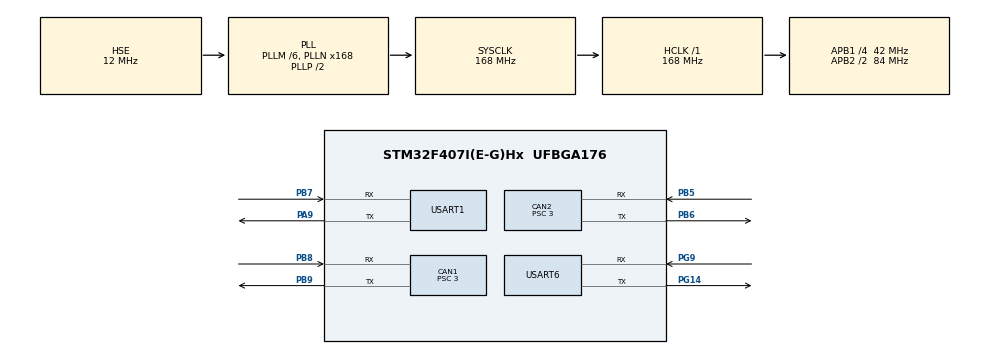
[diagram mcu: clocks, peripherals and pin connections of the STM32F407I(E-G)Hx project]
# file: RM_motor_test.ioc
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CAN1.BS1=CAN_BS1_10TQ
CAN1.BS2=CAN_BS2_3TQ
CAN1.CalculateBaudRate=1000000
CAN1.CalculateTimeBit=1000
CAN1.CalculateTimeQuantum=71.42857142857143
CAN1.Prescaler=3
CAN2.BS1=CAN_BS1_10TQ
CAN2.BS2=CAN_BS2_3TQ
CAN2.CalculateBaudRate=1000000
CAN2.CalculateTimeBit=1000
CAN2.CalculateTimeQuantum=71.42857142857143
CAN2.Prescaler=3
FREERTOS.Tasks01=motor_3508,-3,128,control_3508,Default,NULL,Dynamic,NULL,NULL;motor_6020,0,128,control_6020,Default,NULL,Dynamic,NULL,NULL
Mcu.Family=STM32F4
Mcu.Name=STM32F407I(E-G)Hx
Mcu.Package=UFBGA176
NVIC.CAN1_RX0_IRQn=true\:5\:0\:false\:false\:true\:true\:true\:true\:true
NVIC.CAN2_RX0_IRQn=true\:5\:0\:false\:false\:true\:true\:true\:true\:true
NVIC.PriorityGroup=NVIC_PRIORITYGROUP_4
NVIC.USART1_IRQn=true\:5\:0\:false\:false\:true\:true\:true\:true\:true
NVIC.USART6_IRQn=true\:5\:0\:false\:false\:true\:true\:true\:true\:true
PA13.Mode=Serial_Wire
PA13.Signal=SYS_JTMS-SWDIO
PA14.Mode=Serial_Wire
PA14.Signal=SYS_JTCK-SWCLK
PA9.Mode=Asynchronous
PA9.Signal=USART1_TX
PB5.Mode=CAN_Activate
PB5.Signal=CAN2_RX
PB6.Mode=CAN_Activate
PB6.Signal=CAN2_TX
PB7.Mode=Asynchronous
PB7.Signal=USART1_RX
PB8.Mode=CAN_Activate
PB8.Signal=CAN1_RX
PB9.Mode=CAN_Activate
PB9.Signal=CAN1_TX
PG14.Mode=Asynchronous
PG14.Signal=USART6_TX
PG9.Mode=Asynchronous
PG9.Signal=USART6_RX
PH0-OSC_IN.Mode=HSE-External-Oscillator
PH0-OSC_IN.Signal=RCC_OSC_IN
PH1-OSC_OUT.Mode=HSE-External-Oscillator
PH1-OSC_OUT.Signal=RCC_OSC_OUT
ProjectManager.HeapSize=0x200
ProjectManager.StackSize=0x400
ProjectManager.TargetToolchain=MDK-ARM V5
RCC.48MHZClocksFreq_Value=84000000
RCC.AHBFreq_Value=168000000
RCC.APB1CLKDivider=RCC_HCLK_DIV4
RCC.APB1Freq_Value=42000000
RCC.APB1TimFreq_Value=84000000
RCC.APB2CLKDivider=RCC_HCLK_DIV2
RCC.APB2Freq_Value=84000000
RCC.APB2TimFreq_Value=168000000
RCC.CortexFreq_Value=168000000
RCC.HCLKFreq_Value=168000000
RCC.HSE_VALUE=12000000
RCC.HSI_VALUE=16000000
RCC.LSE_VALUE=32768
RCC.PLLM=6
RCC.PLLN=168
RCC.PLLSourceVirtual=RCC_PLLSOURCE_HSE
RCC.SYSCLKFreq_VALUE=168000000
RCC.SYSCLKSource=RCC_SYSCLKSOURCE_PLLCLK
RCC.VCOOutputFreq_Value=336000000
USART1.VirtualMode=VM_ASYNC
USART6.VirtualMode=VM_ASYNC
VP_FREERTOS_VS_CMSIS_V1.Mode=CMSIS_V1
board=custom

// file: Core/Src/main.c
/* USER CODE BEGIN Header */
/**
  ******************************************************************************
  * @file           : main.c
  * @brief          : Main program body
  ******************************************************************************
  * @attention
  *
  * Copyright (c) 2025 STMicroelectronics.
  * All rights reserved.
  *
  * This software is licensed under terms that can be found in the LICENSE file
  * in the root directory of this software component.
  * If no LICENSE file comes with this software, it is provided AS-IS.
  *
  ******************************************************************************
  */
/* USER CODE END Header */
#include "main.h"
#include "cmsis_os.h"
#include "can.h"
#include "usart.h"
#include "gpio.h"

void SystemClock_Config(void);
void MX_FREERTOS_Init(void);

int main(void)
{

  /* MCU Configuration--------------------------------------------------------*/

  /* Reset of all peripherals, Initializes the Flash interface and the Systick. */
  HAL_Init();

  /* Configure the system clock */
  SystemClock_Config();

  /* Initialize all configured peripherals */
  MX_GPIO_Init();
  MX_CAN1_Init();
  MX_CAN2_Init();
  MX_USART1_UART_Init();
  MX_USART6_UART_Init();

  /* Call init function for freertos objects (in cmsis_os2.c) */
  MX_FREERTOS_Init();

  /* Start scheduler */
  osKernelStart();

  /* We should never get here as control is now taken by the scheduler */

  /* Infinite loop */
  while (1)
  {

  }
}

void SystemClock_Config(void)
{
  RCC_OscInitTypeDef RCC_OscInitStruct = {0};
  RCC_ClkInitTypeDef RCC_ClkInitStruct = {0};

  /** Configure the main internal regulator output voltage
  */
  __HAL_RCC_PWR_CLK_ENABLE();
  __HAL_PWR_VOLTAGESCALING_CONFIG(PWR_REGULATOR_VOLTAGE_SCALE1);

  /** Initializes the RCC Oscillators according to the specified parameters
  * in the RCC_OscInitTypeDef structure.
  */
  RCC_OscInitStruct.OscillatorType = RCC_OSCILLATORTYPE_HSE;
  RCC_OscInitStruct.HSEState = RCC_HSE_ON;
  RCC_OscInitStruct.PLL.PLLState = RCC_PLL_ON;
  RCC_OscInitStruct.PLL.PLLSource = RCC_PLLSOURCE_HSE;
  RCC_OscInitStruct.PLL.PLLM = 6;
  RCC_OscInitStruct.PLL.PLLN = 168;
  RCC_OscInitStruct.PLL.PLLP = RCC_PLLP_DIV2;
  RCC_OscInitStruct.PLL.PLLQ = 4;
  if (HAL_RCC_OscConfig(&RCC_OscInitStruct) != HAL_OK)
  {
    Error_Handler();
  }

  /** Initializes the CPU, AHB and APB buses clocks
  */
  RCC_ClkInitStruct.ClockType = RCC_CLOCKTYPE_HCLK|RCC_CLOCKTYPE_SYSCLK
                              |RCC_CLOCKTYPE_PCLK1|RCC_CLOCKTYPE_PCLK2;
  RCC_ClkInitStruct.SYSCLKSource = RCC_SYSCLKSOURCE_PLLCLK;
  RCC_ClkInitStruct.AHBCLKDivider = RCC_SYSCLK_DIV1;
  RCC_ClkInitStruct.APB1CLKDivider = RCC_HCLK_DIV4;
  RCC_ClkInitStruct.APB2CLKDivider = RCC_HCLK_DIV2;

  if (HAL_RCC_ClockConfig(&RCC_ClkInitStruct, FLASH_LATENCY_5) != HAL_OK)
  {
    Error_Handler();
  }
}

void Error_Handler(void)
{
  __disable_irq();
  while (1)
  {
  }
}

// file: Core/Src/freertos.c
/* USER CODE BEGIN Header */
/**
  ******************************************************************************
  * File Name          : freertos.c
  * Description        : Code for freertos applications
  ******************************************************************************
  * @attention
  *
  * Copyright (c) 2025 STMicroelectronics.
  * All rights reserved.
  *
  * This software is licensed under terms that can be found in the LICENSE file
  * in the root directory of this software component.
  * If no LICENSE file comes with this software, it is provided AS-IS.
  *
  ******************************************************************************
  */
/* USER CODE END Header */

#include "FreeRTOS.h"
#include "task.h"
#include "main.h"
#include "cmsis_os.h"
#include "CAN_receive.h"
#include "usart.h"

osThreadId motor_3508Handle;
osThreadId motor_6020Handle;

void control_3508(void const * argument);
void control_6020(void const * argument);

void MX_FREERTOS_Init(void); /* (MISRA C 2004 rule 8.1) */

/* GetIdleTaskMemory prototype (linked to static allocation support) */
void vApplicationGetIdleTaskMemory( StaticTask_t **ppxIdleTaskTCBBuffer, StackType_t **ppxIdleTaskStackBuffer, uint32_t *pulIdleTaskStackSize );

/* USER CODE BEGIN GET_IDLE_TASK_MEMORY */
static StaticTask_t xIdleTaskTCBBuffer;
static StackType_t xIdleStack[configMINIMAL_STACK_SIZE];

void vApplicationGetIdleTaskMemory( StaticTask_t **ppxIdleTaskTCBBuffer, StackType_t **ppxIdleTaskStackBuffer, uint32_t *pulIdleTaskStackSize )
{
  *ppxIdleTaskTCBBuffer = &xIdleTaskTCBBuffer;
  *ppxIdleTaskStackBuffer = &xIdleStack[0];
  *pulIdleTaskStackSize = configMINIMAL_STACK_SIZE;
  /* place for user code */
}
/* USER CODE END GET_IDLE_TASK_MEMORY */

void MX_FREERTOS_Init(void) {

  /* Create the thread(s) */
  /* definition and creation of motor_3508 */
  osThreadDef(motor_3508, control_3508, osPriorityIdle, 0, 128);
  motor_3508Handle = osThreadCreate(osThread(motor_3508), NULL);

  /* definition and creation of motor_6020 */
  osThreadDef(motor_6020, control_6020, osPriorityNormal, 0, 128);
  motor_6020Handle = osThreadCreate(osThread(motor_6020), NULL);

}

void control_3508(void const * argument)
{
  /* USER CODE BEGIN control_3508 */
  /* Infinite loop */
  for(;;)
  {
		control_motor_3508();
    osDelay(1);
  }
  /* USER CODE END control_3508 */
}

void control_6020(void const * argument)
{
  /* USER CODE BEGIN control_6020 */
  /* Infinite loop */
  for(;;)
  {
		control_motor_6020();
    osDelay(1);
  }
  /* USER CODE END control_6020 */
}
